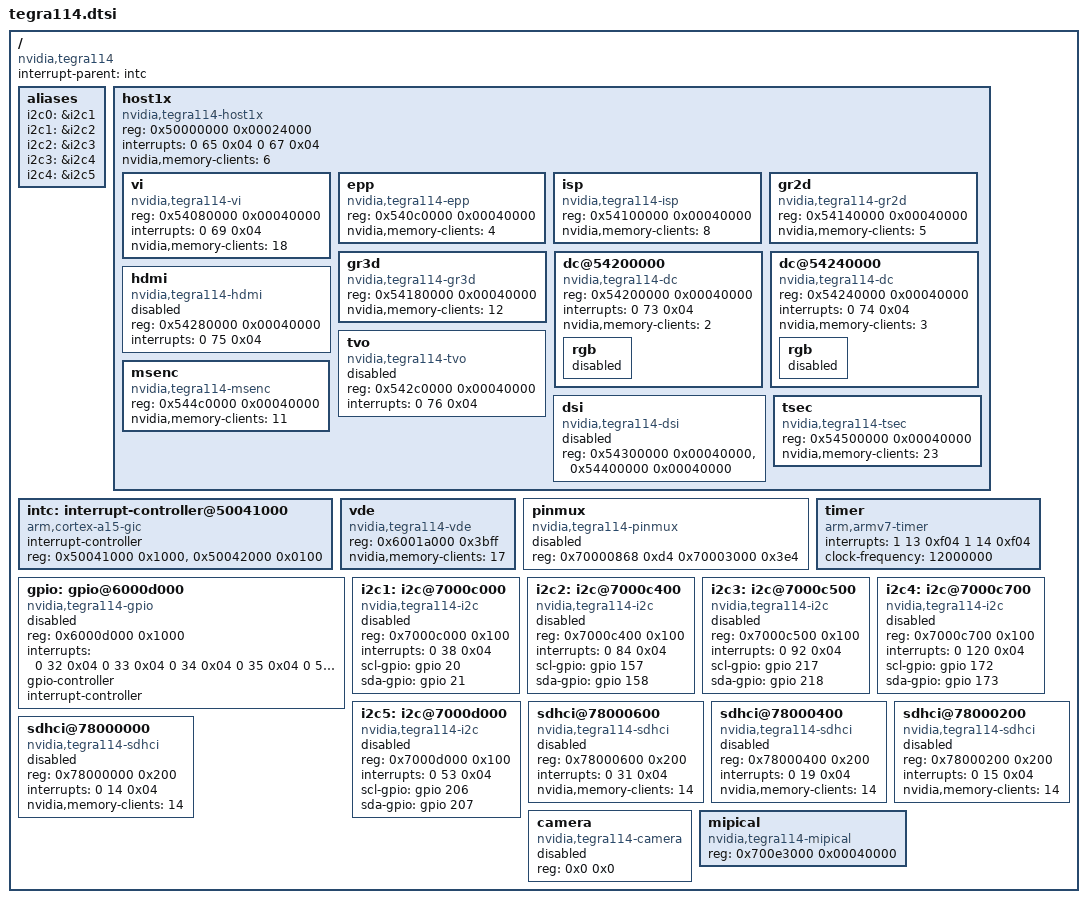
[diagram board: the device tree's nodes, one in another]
/include/ "skeleton.dtsi"

/ {
	compatible = "nvidia,tegra114";
	interrupt-parent = <&intc>;

	aliases {
		i2c0 = &i2c1;
		i2c1 = &i2c2;
		i2c2 = &i2c3;
		i2c3 = &i2c4;
		i2c4 = &i2c5;
	};

	host1x {
		compatible = "nvidia,tegra114-host1x", "simple-bus";
		reg = <0x50000000 0x00024000>;
		interrupts = <0 65 0x04   /* mpcore syncpt */
			      0 67 0x04>; /* mpcore general */
		nvidia,memory-clients = <6>;

		#address-cells = <1>;
		#size-cells = <1>;

		ranges = <0x54000000 0x54000000 0x01000000>;

		vi {
			compatible = "nvidia,tegra114-vi";
			reg = <0x54080000 0x00040000>;
			interrupts = <0 69 0x04>;
			nvidia,memory-clients = <18>;
		};

		epp {
			compatible = "nvidia,tegra114-epp";
			reg = <0x540c0000 0x00040000>;
			nvidia,memory-clients = <4>;
		};

		isp {
			compatible = "nvidia,tegra114-isp";
			reg = <0x54100000 0x00040000>;
			nvidia,memory-clients = <8>;
		};

		gr2d {
			compatible = "nvidia,tegra114-gr2d";
			reg = <0x54140000 0x00040000>;
			nvidia,memory-clients = <5>;
		};

		gr3d {
			compatible = "nvidia,tegra114-gr3d";
			reg = <0x54180000 0x00040000>;
			nvidia,memory-clients = <12>;
		};

		dc@54200000 {
			compatible = "nvidia,tegra114-dc";
			reg = <0x54200000 0x00040000>;
			interrupts = <0 73 0x04>;
			nvidia,memory-clients = <2>;

			rgb {
				status = "disabled";
			};
		};

		dc@54240000 {
			compatible = "nvidia,tegra114-dc";
			reg = <0x54240000 0x00040000>;
			interrupts = <0 74 0x04>;
			nvidia,memory-clients = <3>;

			rgb {
				status = "disabled";
			};
		};

		hdmi {
			compatible = "nvidia,tegra114-hdmi";
			reg = <0x54280000 0x00040000>;
			interrupts = <0 75 0x04>;
			status = "disabled";
		};

		tvo {
			compatible = "nvidia,tegra114-tvo";
			reg = <0x542c0000 0x00040000>;
			interrupts = <0 76 0x04>;
			status = "disabled";
		};

		dsi {
			compatible = "nvidia,tegra114-dsi";
			reg = <0x54300000 0x00040000>,
			      <0x54400000 0x00040000>;
			status = "disabled";
		};

		msenc {
			compatible = "nvidia,tegra114-msenc";
			reg = <0x544c0000 0x00040000>;
			nvidia,memory-clients = <11>;
		};

		tsec {
			compatible = "nvidia,tegra114-tsec";
			reg = <0x54500000 0x00040000>;
			nvidia,memory-clients = <23>;
		};
	};

	intc: interrupt-controller@50041000 {
		compatible = "arm,cortex-a15-gic";
		interrupt-controller;
		#interrupt-cells = <3>;
		reg = <0x50041000 0x1000>,
		      <0x50042000 0x0100>;
	};

	vde {
		reg = <0x6001a000 0x3bff>;
		compatible = "nvidia,tegra114-vde";
		nvidia,memory-clients = <17>;
	};

	pinmux: pinmux {
		compatible = "nvidia,tegra114-pinmux";
		reg = <0x70000868 0xd4    /* Pad control registers */
		       0x70003000 0x3e4>; /* Mux registers */
		status = "disable";
	};

	timer {
		compatible = "arm,armv7-timer";
		interrupts = <1 13 0xf04
			      1 14 0xf04>;
		clock-frequency = <12000000>;
	};

	gpio: gpio@6000d000 {
		compatible = "nvidia,tegra114-gpio", "nvidia,tegra30-gpio";
		reg = <0x6000d000 0x1000>;
		interrupts = <0 32 0x04
				0 33 0x04
				0 34 0x04
				0 35 0x04
				0 55 0x04
				0 87 0x04
				0 89 0x04
				0 125 0x04>;
		#gpio-cells = <2>;
		gpio-controller;
		#interrupt-cells = <2>;
		interrupt-controller;
		status = "disable";
	};

	i2c1: i2c@7000c000 {
		#address-cells = <1>;
		#size-cells = <0>;
		compatible = "nvidia,tegra114-i2c";
		reg = <0x7000c000 0x100>;
		interrupts = <0 38 0x04>;
		scl-gpio = <&gpio 20 0>; /* gpio PC4 */
		sda-gpio = <&gpio 21 0>; /* gpio PC5 */
		status = "disable";
	};

	i2c2: i2c@7000c400 {
		#address-cells = <1>;
		#size-cells = <0>;
		compatible = "nvidia,tegra114-i2c";
		reg = <0x7000c400 0x100>;
		interrupts = <0 84 0x04>;
		scl-gpio = <&gpio 157 0>; /* gpio PT5 */
		sda-gpio = <&gpio 158 0>; /* gpio PT6 */
		status = "disable";
	};

	i2c3: i2c@7000c500 {
		#address-cells = <1>;
		#size-cells = <0>;
		compatible = "nvidia,tegra114-i2c";
		reg = <0x7000c500 0x100>;
		interrupts = <0 92 0x04>;
		scl-gpio = <&gpio 217 0>; /* gpio PBB1 */
		sda-gpio = <&gpio 218 0>; /* gpio PBB2 */
		status = "disable";
	};

	i2c4: i2c@7000c700 {
		#address-cells = <1>;
		#size-cells = <0>;
		compatible = "nvidia,tegra114-i2c";
		reg = <0x7000c700 0x100>;
		interrupts = <0 120 0x04>;
		scl-gpio = <&gpio 172 0>; /* gpio PV4 */
		sda-gpio = <&gpio 173 0>; /* gpio PV5 */
		status = "disable";
	};

	i2c5: i2c@7000d000 {
		#address-cells = <1>;
		#size-cells = <0>;
		compatible = "nvidia,tegra114-i2c";
		reg = <0x7000d000 0x100>;
		interrupts = <0 53 0x04>;
		scl-gpio = <&gpio 206 0>; /* gpio PZ6 */
		sda-gpio = <&gpio 207 0>; /* gpio PZ7 */
		status = "disable";
	};

	sdhci@78000600 {
		compatible = "nvidia,tegra114-sdhci", "nvidia,tegra20-sdhci";
		reg = <0x78000600 0x200>;
		interrupts = < 0 31 0x04 >;
		nvidia,memory-clients = <14>;
		status = "disable";
	};
	sdhci@78000400 {
		compatible = "nvidia,tegra114-sdhci", "nvidia,tegra20-sdhci";
		reg = <0x78000400 0x200>;
		interrupts = < 0 19 0x04 >;
		nvidia,memory-clients = <14>;
		status = "disable";
	};
	sdhci@78000200 {
		compatible = "nvidia,tegra114-sdhci", "nvidia,tegra20-sdhci";
		reg = <0x78000200 0x200>;
		interrupts = < 0 15 0x04 >;
		nvidia,memory-clients = <14>;
		status = "disable";
	};
	sdhci@78000000 {
		compatible = "nvidia,tegra114-sdhci", "nvidia,tegra20-sdhci";
		reg = <0x78000000 0x200>;
		interrupts = < 0 14 0x04 >;
		nvidia,memory-clients = <14>;
		status = "disable";
	};

	camera {
		compatible = "nvidia,tegra114-camera", "nvidia,tegra20-camera";
		reg = <0x0 0x0>;
		status = "disable";
	};

	mipical {
		compatible = "nvidia,tegra114-mipical";
		reg = <0x700e3000 0x00040000>;
	};
};
